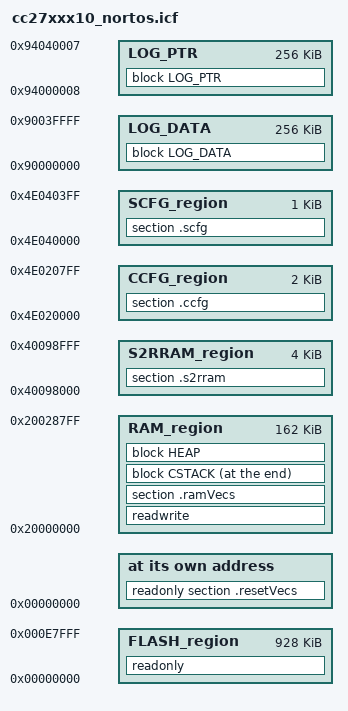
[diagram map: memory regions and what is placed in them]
/*
 * Copyright (c) 2023-2024, Texas Instruments Incorporated
 * All rights reserved.
 *
 * Redistribution and use in source and binary forms, with or without
 * modification, are permitted provided that the following conditions
 * are met:
 *
 * *  Redistributions of source code must retain the above copyright
 *    notice, this list of conditions and the following disclaimer.
 *
 * *  Redistributions in binary form must reproduce the above copyright
 *    notice, this list of conditions and the following disclaimer in the
 *    documentation and/or other materials provided with the distribution.
 *
 * *  Neither the name of Texas Instruments Incorporated nor the names of
 *    its contributors may be used to endorse or promote products derived
 *    from this software without specific prior written permission.
 *
 * THIS SOFTWARE IS PROVIDED BY THE COPYRIGHT HOLDERS AND CONTRIBUTORS "AS IS"
 * AND ANY EXPRESS OR IMPLIED WARRANTIES, INCLUDING, BUT NOT LIMITED TO,
 * THE IMPLIED WARRANTIES OF MERCHANTABILITY AND FITNESS FOR A PARTICULAR
 * PURPOSE ARE DISCLAIMED. IN NO EVENT SHALL THE COPYRIGHT OWNER OR
 * CONTRIBUTORS BE LIABLE FOR ANY DIRECT, INDIRECT, INCIDENTAL, SPECIAL,
 * EXEMPLARY, OR CONSEQUENTIAL DAMAGES (INCLUDING, BUT NOT LIMITED TO,
 * PROCUREMENT OF SUBSTITUTE GOODS OR SERVICES; LOSS OF USE, DATA, OR PROFITS;
 * OR BUSINESS INTERRUPTION) HOWEVER CAUSED AND ON ANY THEORY OF LIABILITY,
 * WHETHER IN CONTRACT, STRICT LIABILITY, OR TORT (INCLUDING NEGLIGENCE OR
 * OTHERWISE) ARISING IN ANY WAY OUT OF THE USE OF THIS SOFTWARE,
 * EVEN IF ADVISED OF THE POSSIBILITY OF SUCH DAMAGE.
 */
include "../lpf3/cc27xx_crc_linker_symbols.icf";

define symbol __intvec_start__ = 0x00000000;

/* The HSM FW is 96KB */
define symbol HSM_FW_SIZE = 0x18000;

/*-Memory Regions-*/
/* Flash Memory Region.
 * The last part of Flash is reserved for the HSM FW.
 */
define symbol ROM_start__ = 0x00000000;
define symbol ROM_end__   = 0x000FFFFF - HSM_FW_SIZE;

/* RAM Memory Region */
define symbol RAM_start__ = 0x20000000;
define symbol RAM_end__   = 0x200287FF;

/* S2RRAM Memory Region */
define symbol S2RRAM_start__ = 0x40098000;
define symbol S2RRAM_end__   = 0x40098FFF;

/* CCFG Memory Region */
define symbol CCFG_START__ = 0x4E020000;
define symbol CCFG_END__   = 0x4E0207FF;

/* SCFG Memory Region */
define symbol SCFG_START__ = 0x4E040000;
define symbol SCFG_END__   = 0x4E0403FF;

/* Define a memory region that covers the entire 4 GB addressable space */
define memory mem with size = 4G;

/* Define a region for the on-chip flash */
define region FLASH_region = mem:[from ROM_start__ to ROM_end__];

/* Define a region for the on-chip SRAM */
define region RAM_region = mem:[from RAM_start__ to RAM_end__];

/* Define a region for the on-chip S2RRAM
 * S2RRAM is intended for the S2R radio module, but it can also be used by the
 * application with some limitations. Please refer to the s2rram example.
 */
define region S2RRAM_region = mem:[from S2RRAM_start__ to S2RRAM_end__];
/* Placing the section .s2rram in S2RRAM region. Only uninitialized
 * objects may be placed in this section.
 */
place in S2RRAM_region { section .s2rram };
do not initialize { section .s2rram };

/* Place the interrupt vectors at the start of flash */
place at address mem:__intvec_start__ { readonly section .resetVecs };
keep { section .resetVecs };

/* Define a region for CCFG */
define region CCFG_region = mem:[from CCFG_START__ to CCFG_END__];
place in CCFG_region {section .ccfg};
keep { section .ccfg };

/* Define a region for SCFG */
define region SCFG_region = mem:[from SCFG_START__ to SCFG_END__];
place in SCFG_region {section .scfg};
keep { section .scfg };

/*
 * Define symbols required for CRC32 checksum generation within CCFG and SCFG.
 * Post-build step example:
 * ielftool --checksum __ccfg_boot_cfg_crc32_end+1:4,crc32:1mi,0xFFFFFFFF;__ccfg_boot_cfg_crc32_begin-__ccfg_boot_cfg_crc32_end
 *          --checksum __ccfg_crc32_end+1:4,crc32:1mi,0xFFFFFFFF;__ccfg_crc32_begin-__ccfg_crc32_end
 *          --checksum __ccfg_user_record_crc32_end+1:4,crc32:1mi,0xFFFFFFFF;__ccfg_user_record_crc32_begin-__ccfg_user_record_crc32_end
 *          --checksum __ccfg_debug_cfg_crc32_end+1:4,crc32:1mi,0xFFFFFFFF;__ccfg_debug_cfg_crc32_begin-__ccfg_debug_cfg_crc32_end
 *          --checksum __scfg_crc32_end+1:4,crc32:1mi,0xFFFFFFFF;__scfg_crc32_begin-__scfg_crc32_end
 *          "$TARGET_PATH$" "$TARGET_PATH$"
 */
define exported symbol __ccfg_boot_cfg_crc32_begin      = 0x4E020000;
define exported symbol __ccfg_boot_cfg_crc32_end        = 0x4E02000B;
define exported symbol __ccfg_crc32_begin               = 0x4E020010;
define exported symbol __ccfg_crc32_end                 = 0x4E02074B;
define exported symbol __ccfg_user_record_crc32_begin   = 0x4E020750;
define exported symbol __ccfg_user_record_crc32_end     = 0x4E0207CB;
define exported symbol __ccfg_debug_cfg_crc32_begin     = 0x4E0207D0;
define exported symbol __ccfg_debug_cfg_crc32_end       = 0x4E0207FB;
define exported symbol __scfg_crc32_begin               = 0x4E040000;
define exported symbol __scfg_crc32_end                 = 0x4E0400E3;

/* Place remaining 'read only' in Flash */
place in FLASH_region { readonly };

/* Place all read/write items into RAM */
place in RAM_region   { readwrite, section .ramVecs };
initialize by copy { readwrite };
do not initialize { section .ramVecs };

/*
 * Define CSTACK block to contain .stack section. This enables the IAR IDE
 * to properly show the stack content during debug. Place stack at end of
 * retention RAM, do not initialize (initializing the stack will destroy the
 * return address from the initialization code, causing the processor to branch
 * to zero and fault)
 */
define symbol STACKSIZE = 1024;
define block CSTACK with alignment = 8, size = STACKSIZE { section .stack };
place at end of RAM_region { block CSTACK };
do not initialize { section .stack, section .noinit };

/* Export stack top symbol. Used by startup file */
define exported symbol STACK_TOP = RAM_end__ + 1;

/* Primary Heap configuration */
define symbol HEAPSIZE = 16384;
define block HEAP with alignment = 8, size = HEAPSIZE { };

/* Place heap just before CSTACK */
place in RAM_region { block HEAP };

/* Explicitly placed off target for the storage of logging data.
 * The data placed here is NOT  loaded ont the target device.
 * This is part of 1 GB of external memory from 0x60000000 - 0x9FFFFFFF.
 * ARM memory map can be found here:
 * https://developer.arm.com/documentation/ddi0337/e/memory-map/about-the-memory-map
 */
define region LOG_DATA = mem:[from 0x90000000 to 0x9003FFFF];
define region LOG_PTR = mem:[from 0x94000008 to 0x94040007];
define block LOG_DATA  with size = 0x40000 { readonly section .log_data  };
define block LOG_PTR   with size = 0x40000 { readonly section .log_ptr* };
".log_data": place noload in LOG_DATA { block LOG_DATA };
".log_ptr": place noload in LOG_PTR { block LOG_PTR };
